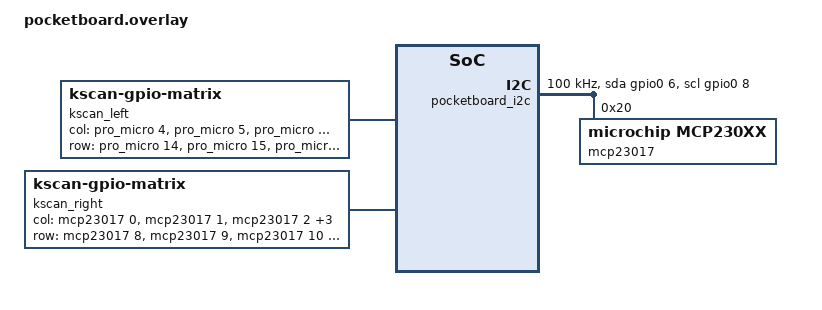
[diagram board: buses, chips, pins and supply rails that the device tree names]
#include "pocketboard.dtsi"
#include <zephyr/dt-bindings/gpio/gpio.h>

/*
 * PocketBoard-Corne-HW1 v7
 * Left matrix on nice!nano + right matrix on MCP23017 @ 0x20.
 * v7 switches the inter-half bus from hardware TWIM to GPIO bit-banged I2C
 * on the exact physical pins already wired in HW1:
 *   SDA = D1 / P0.06
 *   SCL = D0 / P0.08
 */

/* These pins must not be owned by UART while used by software I2C. */
&uart0 {
    status = "disabled";
};

/* Hardware I2C0 is intentionally disabled in v7. */
&i2c0 {
    status = "disabled";
};

/ {
    /*
     * Software I2C on GPIOs.
     * Internal pull-ups are requested here, so no new external resistor
     * is required for this diagnostic/functional test.
     */
    pocketboard_i2c: i2c_gpio {
        compatible = "gpio-i2c";
        status = "okay";
        #address-cells = <1>;
        #size-cells = <0>;
        clock-frequency = <100000>;

        sda-gpios = <&gpio0 6 (GPIO_ACTIVE_HIGH | GPIO_OPEN_DRAIN | GPIO_PULL_UP)>;
        scl-gpios = <&gpio0 8 (GPIO_ACTIVE_HIGH | GPIO_OPEN_DRAIN | GPIO_PULL_UP)>;

        mcp23017: gpio@20 {
            compatible = "microchip,mcp230xx";
            reg = <0x20>;
            gpio-controller;
            #gpio-cells = <2>;
            ngpios = <16>;
            status = "okay";
        };
    };

    kscan_left: kscan_left {
        compatible = "zmk,kscan-gpio-matrix";
        diode-direction = "col2row";

        col-gpios
            = <&pro_micro 4 GPIO_ACTIVE_HIGH>
            , <&pro_micro 5 GPIO_ACTIVE_HIGH>
            , <&pro_micro 6 GPIO_ACTIVE_HIGH>
            , <&pro_micro 10 GPIO_ACTIVE_HIGH>
            , <&pro_micro 8 GPIO_ACTIVE_HIGH>
            , <&pro_micro 9 GPIO_ACTIVE_HIGH>
            ;

        row-gpios
            = <&pro_micro 14 (GPIO_ACTIVE_HIGH | GPIO_PULL_DOWN)>
            , <&pro_micro 15 (GPIO_ACTIVE_HIGH | GPIO_PULL_DOWN)>
            , <&pro_micro 16 (GPIO_ACTIVE_HIGH | GPIO_PULL_DOWN)>
            , <&pro_micro 18 (GPIO_ACTIVE_HIGH | GPIO_PULL_DOWN)>
            ;

        debounce-press-ms = <5>;
        debounce-release-ms = <5>;
        debounce-scan-period-ms = <1>;
        poll-period-ms = <10>;
    };

    kscan_right: kscan_right {
        compatible = "zmk,kscan-gpio-matrix";
        diode-direction = "col2row";

        col-gpios
            = <&mcp23017 0 GPIO_ACTIVE_HIGH>
            , <&mcp23017 1 GPIO_ACTIVE_HIGH>
            , <&mcp23017 2 GPIO_ACTIVE_HIGH>
            , <&mcp23017 3 GPIO_ACTIVE_HIGH>
            , <&mcp23017 4 GPIO_ACTIVE_HIGH>
            , <&mcp23017 5 GPIO_ACTIVE_HIGH>
            ;

        row-gpios
            = <&mcp23017 8 GPIO_ACTIVE_HIGH>
            , <&mcp23017 9 GPIO_ACTIVE_HIGH>
            , <&mcp23017 10 GPIO_ACTIVE_HIGH>
            , <&mcp23017 11 GPIO_ACTIVE_HIGH>
            ;

        debounce-press-ms = <5>;
        debounce-release-ms = <5>;
        debounce-scan-period-ms = <1>;
        poll-period-ms = <10>;
    };

    kscan0: kscan_composite {
        compatible = "zmk,kscan-composite";
        rows = <8>;
        columns = <12>;

        left {
            kscan = <&kscan_left>;
        };

        right {
            kscan = <&kscan_right>;
            row-offset = <4>;
            column-offset = <6>;
        };
    };
};

&physical_layout_pocketboard {
    kscan = <&kscan0>;
};
